AUTOSAR XML (schema 4-2-2)
package /STELLANTIS/EPT/ASWCs
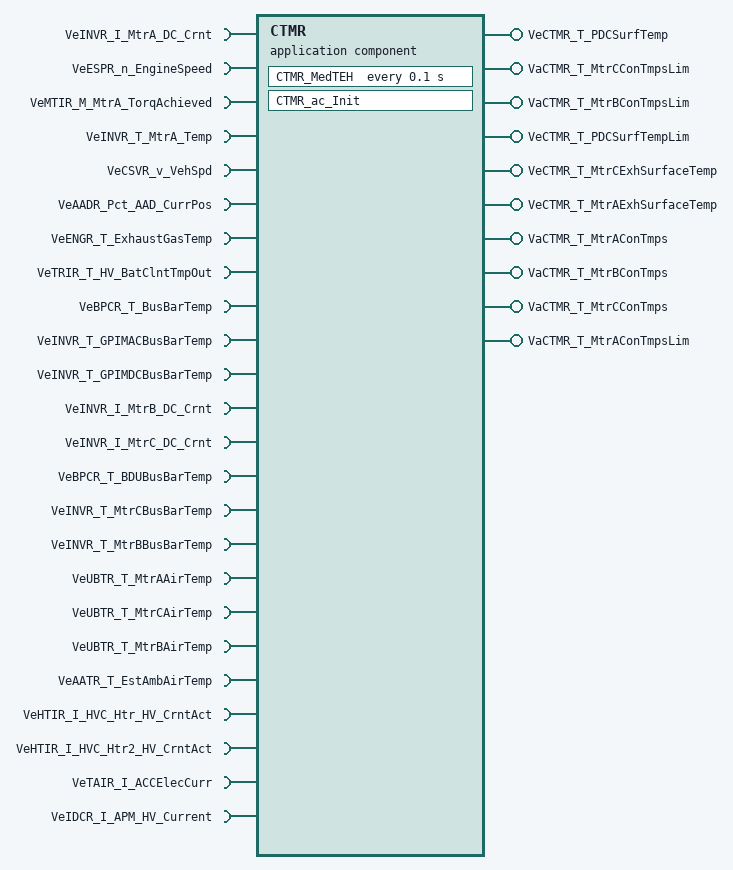
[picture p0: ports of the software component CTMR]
  application sw component type CTMR
    24 x require port, all with nonqueued-receiver-com-spec{data-element=Value, init-value=0}:
      VeINVR_I_MtrA_DC_Crnt: variation-point={short-label=vpVeINVR_I_MtrA_DC_Crnt, sw-syscond=1}, required-interface=VeINVR_I_MtrA_DC_Crnt
      VeESPR_n_EngineSpeed: variation-point={short-label=vpVeESPR_n_EngineSpeed, sw-syscond=1}, required-interface=VeESPR_n_EngineSpeed
      VeMTIR_M_MtrA_TorqAchieved: variation-point={short-label=vpVeMTIR_M_MtrA_TorqAchieved, sw-syscond=1}, required-interface=VeMTIR_M_MtrA_TorqAchieved
      VeINVR_T_MtrA_Temp: variation-point={short-label=vpVeINVR_T_MtrA_Temp, sw-syscond=1}, required-interface=VeINVR_T_MtrA_Temp
      VeCSVR_v_VehSpd: variation-point={short-label=vpVeCSVR_v_VehSpd, sw-syscond=1}, required-interface=VeCSVR_v_VehSpd
      VeAADR_Pct_AAD_CurrPos: variation-point={short-label=vpVeAADR_Pct_AAD_CurrPos, sw-syscond=1}, required-interface=VeAADR_Pct_AAD_CurrPos
      VeENGR_T_ExhaustGasTemp: variation-point={short-label=vpVeENGR_T_ExhaustGasTemp, sw-syscond=1}, required-interface=VeENGR_T_ExhaustGasTemp
      VeTRIR_T_HV_BatClntTmpOut: variation-point={short-label=vpVeTRIR_T_HV_BatClntTmpOut, sw-syscond=1}, required-interface=VeTRIR_T_HV_BatClntTmpOut
      VeBPCR_T_BusBarTemp: variation-point={short-label=vpVeBPCR_T_BusBarTemp, sw-syscond=1}, required-interface=VeBPCR_T_BusBarTemp
      VeINVR_T_GPIMACBusBarTemp: variation-point={short-label=vpVeINVR_T_GPIMACBusBarTemp, sw-syscond=1}, required-interface=VeINVR_T_GPIMACBusBarTemp
      VeINVR_T_GPIMDCBusBarTemp: variation-point={short-label=vpVeINVR_T_GPIMDCBusBarTemp, sw-syscond=1}, required-interface=VeINVR_T_GPIMDCBusBarTemp
      VeINVR_I_MtrB_DC_Crnt: variation-point={short-label=vpVeINVR_I_MtrB_DC_Crnt, sw-syscond=1}, required-interface=VeINVR_I_MtrB_DC_Crnt
      VeINVR_I_MtrC_DC_Crnt: variation-point={short-label=vpVeINVR_I_MtrC_DC_Crnt, sw-syscond=1}, required-interface=VeINVR_I_MtrC_DC_Crnt
      VeBPCR_T_BDUBusBarTemp: variation-point={short-label=vpVeBPCR_T_BDUBusBarTemp, sw-syscond=1}, required-interface=VeBPCR_T_BDUBusBarTemp
      VeINVR_T_MtrCBusBarTemp: variation-point={short-label=vpVeINVR_T_MtrCBusBarTemp, sw-syscond=1}, required-interface=VeINVR_T_MtrCBusBarTemp
      VeINVR_T_MtrBBusBarTemp: variation-point={short-label=vpVeINVR_T_MtrBBusBarTemp, sw-syscond=1}, required-interface=VeINVR_T_MtrBBusBarTemp
      VeUBTR_T_MtrAAirTemp: variation-point={short-label=vpVeUBTR_T_MtrAAirTemp, sw-syscond=1}, required-interface=VeUBTR_T_MtrAAirTemp
      VeUBTR_T_MtrCAirTemp: variation-point={short-label=vpVeUBTR_T_MtrCAirTemp, sw-syscond=1}, required-interface=VeUBTR_T_MtrCAirTemp
      VeUBTR_T_MtrBAirTemp: variation-point={short-label=vpVeUBTR_T_MtrBAirTemp, sw-syscond=1}, required-interface=VeUBTR_T_MtrBAirTemp
      VeAATR_T_EstAmbAirTemp: variation-point={short-label=vpVeAATR_T_EstAmbAirTemp, sw-syscond=1}, required-interface=VeAATR_T_EstAmbAirTemp
      VeHTIR_I_HVC_Htr_HV_CrntAct: variation-point={short-label=vpVeHTIR_I_HVC_Htr_HV_CrntAct, sw-syscond=1}, required-interface=VeHTIR_I_HVC_Htr_HV_CrntAct
      VeHTIR_I_HVC_Htr2_HV_CrntAct: variation-point={short-label=vpVeHTIR_I_HVC_Htr2_HV_CrntAct, sw-syscond=1}, required-interface=VeHTIR_I_HVC_Htr2_HV_CrntAct
      VeTAIR_I_ACCElecCurr: variation-point={short-label=vpVeTAIR_I_ACCElecCurr, sw-syscond=1}, required-interface=VeTAIR_I_ACCElecCurr
      VeIDCR_I_APM_HV_Current: variation-point={short-label=vpVeIDCR_I_APM_HV_Current, sw-syscond=1}, required-interface=VeIDCR_I_APM_HV_Current
    10 x provide port:
      VeCTMR_T_PDCSurfTemp: variation-point={short-label=vpVeCTMR_T_PDCSurfTemp, sw-syscond=1}, nonqueued-sender-com-spec{data-element=Value, init-value=0}, provided-interface=VeCTMR_T_PDCSurfTemp
      VaCTMR_T_MtrCConTmpsLim: variation-point={short-label=vpVaCTMR_T_MtrCConTmpsLim, sw-syscond=1}, nonqueued-sender-com-spec{data-element=Value, init-value=[0, 0]}, provided-interface=VaCTMR_T_MtrCConTmpsLim
      VaCTMR_T_MtrBConTmpsLim: variation-point={short-label=vpVaCTMR_T_MtrBConTmpsLim, sw-syscond=1}, nonqueued-sender-com-spec{data-element=Value, init-value=[0, 0]}, provided-interface=VaCTMR_T_MtrBConTmpsLim
      VeCTMR_T_PDCSurfTempLim: variation-point={short-label=vpVeCTMR_T_PDCSurfTempLim, sw-syscond=1}, nonqueued-sender-com-spec{data-element=Value, init-value=0}, provided-interface=VeCTMR_T_PDCSurfTempLim
      VeCTMR_T_MtrCExhSurfaceTemp: variation-point={short-label=vpVeCTMR_T_MtrCExhSurfaceTemp, sw-syscond=1}, nonqueued-sender-com-spec{data-element=Value, init-value=0}, provided-interface=VeCTMR_T_MtrCExhSurfaceTemp
      VeCTMR_T_MtrAExhSurfaceTemp: variation-point={short-label=vpVeCTMR_T_MtrAExhSurfaceTemp, sw-syscond=1}, nonqueued-sender-com-spec{data-element=Value, init-value=0}, provided-interface=VeCTMR_T_MtrAExhSurfaceTemp
      VaCTMR_T_MtrAConTmps: variation-point={short-label=vpVaCTMR_T_MtrAConTmps, sw-syscond=1}, nonqueued-sender-com-spec{data-element=Value, init-value=[0, 0, 0, 0]}, provided-interface=VaCTMR_T_MtrAConTmps
      VaCTMR_T_MtrBConTmps: variation-point={short-label=vpVaCTMR_T_MtrBConTmps, sw-syscond=1}, nonqueued-sender-com-spec{data-element=Value, init-value=[0, 0]}, provided-interface=VaCTMR_T_MtrBConTmps
      VaCTMR_T_MtrCConTmps: variation-point={short-label=vpVaCTMR_T_MtrCConTmps, sw-syscond=1}, nonqueued-sender-com-spec{data-element=Value, init-value=[0, 0]}, provided-interface=VaCTMR_T_MtrCConTmps
      VaCTMR_T_MtrAConTmpsLim: variation-point={short-label=vpVaCTMR_T_MtrAConTmpsLim, sw-syscond=1}, nonqueued-sender-com-spec{data-element=Value, init-value=[0, 0, 0, 0]}, provided-interface=VaCTMR_T_MtrAConTmpsLim
    behavior IB_CTMR: data-type-mapping=msADTtoIDTMapping, handle-termination-and-restart=NO-SUPPORT
      timing event Event_MedTEH: start-on-event=CTMR_MedTEH, period=0.1
      init event Event_CTMR_ac_Init: start-on-event=CTMR_ac_Init
      runnable CTMR_ac_Init
        data-send-points:
          6 x access:
            OUT_VaCTMR_T_MtrCConTmpsLim_Value: accessed-variable=VaCTMR_T_MtrCConTmpsLim.Value, variation-point={short-label=vpOUT_VaCTMR_T_MtrCConTmpsLim_Value, sw-syscond=1}
            OUT_VaCTMR_T_MtrBConTmpsLim_Value: accessed-variable=VaCTMR_T_MtrBConTmpsLim.Value, variation-point={short-label=vpOUT_VaCTMR_T_MtrBConTmpsLim_Value, sw-syscond=1}
            OUT_VaCTMR_T_MtrAConTmps_Value: accessed-variable=VaCTMR_T_MtrAConTmps.Value, variation-point={short-label=vpOUT_VaCTMR_T_MtrAConTmps_Value, sw-syscond=1}
            OUT_VaCTMR_T_MtrBConTmps_Value: accessed-variable=VaCTMR_T_MtrBConTmps.Value, variation-point={short-label=vpOUT_VaCTMR_T_MtrBConTmps_Value, sw-syscond=1}
            OUT_VaCTMR_T_MtrCConTmps_Value: accessed-variable=VaCTMR_T_MtrCConTmps.Value, variation-point={short-label=vpOUT_VaCTMR_T_MtrCConTmps_Value, sw-syscond=1}
            OUT_VaCTMR_T_MtrAConTmpsLim_Value: accessed-variable=VaCTMR_T_MtrAConTmpsLim.Value, variation-point={short-label=vpOUT_VaCTMR_T_MtrAConTmpsLim_Value, sw-syscond=1}
      runnable CTMR_MedTEH: variation-point={short-label=vpCTMR_MedTEH, sw-syscond=1}
        data-receive-point-by-arguments:
          24 x access:
            IN_VeAADR_Pct_AAD_CurrPos_Value: accessed-variable=VeAADR_Pct_AAD_CurrPos.Value, variation-point={short-label=vpIN_VeAADR_Pct_AAD_CurrPos_Value, sw-syscond=1}
            IN_VeAATR_T_EstAmbAirTemp_Value: accessed-variable=VeAATR_T_EstAmbAirTemp.Value, variation-point={short-label=vpIN_VeAATR_T_EstAmbAirTemp_Value, sw-syscond=1}
            IN_VeBPCR_T_BDUBusBarTemp_Value: accessed-variable=VeBPCR_T_BDUBusBarTemp.Value, variation-point={short-label=vpIN_VeBPCR_T_BDUBusBarTemp_Value, sw-syscond=1}
            IN_VeBPCR_T_BusBarTemp_Value: accessed-variable=VeBPCR_T_BusBarTemp.Value, variation-point={short-label=vpIN_VeBPCR_T_BusBarTemp_Value, sw-syscond=1}
            IN_VeCSVR_v_VehSpd_Value: accessed-variable=VeCSVR_v_VehSpd.Value, variation-point={short-label=vpIN_VeCSVR_v_VehSpd_Value, sw-syscond=1}
            IN_VeENGR_T_ExhaustGasTemp_Value: accessed-variable=VeENGR_T_ExhaustGasTemp.Value, variation-point={short-label=vpIN_VeENGR_T_ExhaustGasTemp_Value, sw-syscond=1}
            IN_VeESPR_n_EngineSpeed_Value: accessed-variable=VeESPR_n_EngineSpeed.Value, variation-point={short-label=vpIN_VeESPR_n_EngineSpeed_Value, sw-syscond=1}
            IN_VeHTIR_I_HVC_Htr2_HV_CrntAct_Value: accessed-variable=VeHTIR_I_HVC_Htr2_HV_CrntAct.Value, variation-point={short-label=vpIN_VeHTIR_I_HVC_Htr2_HV_CrntAct_Value, sw-syscond=1}
            IN_VeHTIR_I_HVC_Htr_HV_CrntAct_Value: accessed-variable=VeHTIR_I_HVC_Htr_HV_CrntAct.Value, variation-point={short-label=vpIN_VeHTIR_I_HVC_Htr_HV_CrntAct_Value, sw-syscond=1}
            IN_VeIDCR_I_APM_HV_Current_Value: accessed-variable=VeIDCR_I_APM_HV_Current.Value, variation-point={short-label=vpIN_VeIDCR_I_APM_HV_Current_Value, sw-syscond=1}
            IN_VeINVR_I_MtrA_DC_Crnt_Value: accessed-variable=VeINVR_I_MtrA_DC_Crnt.Value, variation-point={short-label=vpIN_VeINVR_I_MtrA_DC_Crnt_Value, sw-syscond=1}
            IN_VeINVR_I_MtrB_DC_Crnt_Value: accessed-variable=VeINVR_I_MtrB_DC_Crnt.Value, variation-point={short-label=vpIN_VeINVR_I_MtrB_DC_Crnt_Value, sw-syscond=1}
            IN_VeINVR_I_MtrC_DC_Crnt_Value: accessed-variable=VeINVR_I_MtrC_DC_Crnt.Value, variation-point={short-label=vpIN_VeINVR_I_MtrC_DC_Crnt_Value, sw-syscond=1}
            IN_VeINVR_T_GPIMACBusBarTemp_Value: accessed-variable=VeINVR_T_GPIMACBusBarTemp.Value, variation-point={short-label=vpIN_VeINVR_T_GPIMACBusBarTemp_Value, sw-syscond=1}
            IN_VeINVR_T_GPIMDCBusBarTemp_Value: accessed-variable=VeINVR_T_GPIMDCBusBarTemp.Value, variation-point={short-label=vpIN_VeINVR_T_GPIMDCBusBarTemp_Value, sw-syscond=1}
            IN_VeINVR_T_MtrA_Temp_Value: accessed-variable=VeINVR_T_MtrA_Temp.Value, variation-point={short-label=vpIN_VeINVR_T_MtrA_Temp_Value, sw-syscond=1}
            IN_VeINVR_T_MtrBBusBarTemp_Value: accessed-variable=VeINVR_T_MtrBBusBarTemp.Value, variation-point={short-label=vpIN_VeINVR_T_MtrBBusBarTemp_Value, sw-syscond=1}
            IN_VeINVR_T_MtrCBusBarTemp_Value: accessed-variable=VeINVR_T_MtrCBusBarTemp.Value, variation-point={short-label=vpIN_VeINVR_T_MtrCBusBarTemp_Value, sw-syscond=1}
            IN_VeMTIR_M_MtrA_TorqAchieved_Value: accessed-variable=VeMTIR_M_MtrA_TorqAchieved.Value, variation-point={short-label=vpIN_VeMTIR_M_MtrA_TorqAchieved_Value, sw-syscond=1}
            IN_VeTAIR_I_ACCElecCurr_Value: accessed-variable=VeTAIR_I_ACCElecCurr.Value, variation-point={short-label=vpIN_VeTAIR_I_ACCElecCurr_Value, sw-syscond=1}
            IN_VeTRIR_T_HV_BatClntTmpOut_Value: accessed-variable=VeTRIR_T_HV_BatClntTmpOut.Value, variation-point={short-label=vpIN_VeTRIR_T_HV_BatClntTmpOut_Value, sw-syscond=1}
            IN_VeUBTR_T_MtrAAirTemp_Value: accessed-variable=VeUBTR_T_MtrAAirTemp.Value, variation-point={short-label=vpIN_VeUBTR_T_MtrAAirTemp_Value, sw-syscond=1}
            IN_VeUBTR_T_MtrBAirTemp_Value: accessed-variable=VeUBTR_T_MtrBAirTemp.Value, variation-point={short-label=vpIN_VeUBTR_T_MtrBAirTemp_Value, sw-syscond=1}
            IN_VeUBTR_T_MtrCAirTemp_Value: accessed-variable=VeUBTR_T_MtrCAirTemp.Value, variation-point={short-label=vpIN_VeUBTR_T_MtrCAirTemp_Value, sw-syscond=1}
        data-send-points:
          10 x access:
            OUT_VeCTMR_T_PDCSurfTempLim_Value: accessed-variable=VeCTMR_T_PDCSurfTempLim.Value, variation-point={short-label=vpOUT_VeCTMR_T_PDCSurfTempLim_Value, sw-syscond=1}
            OUT_VaCTMR_T_MtrAConTmps_Value: accessed-variable=VaCTMR_T_MtrAConTmps.Value, variation-point={short-label=vpOUT_VaCTMR_T_MtrAConTmps_Value, sw-syscond=1}
            OUT_VeCTMR_T_PDCSurfTemp_Value: accessed-variable=VeCTMR_T_PDCSurfTemp.Value, variation-point={short-label=vpOUT_VeCTMR_T_PDCSurfTemp_Value, sw-syscond=1}
            OUT_VaCTMR_T_MtrAConTmpsLim_Value: accessed-variable=VaCTMR_T_MtrAConTmpsLim.Value, variation-point={short-label=vpOUT_VaCTMR_T_MtrAConTmpsLim_Value, sw-syscond=1}
            OUT_VaCTMR_T_MtrBConTmpsLim_Value: accessed-variable=VaCTMR_T_MtrBConTmpsLim.Value, variation-point={short-label=vpOUT_VaCTMR_T_MtrBConTmpsLim_Value, sw-syscond=1}
            OUT_VaCTMR_T_MtrBConTmps_Value: accessed-variable=VaCTMR_T_MtrBConTmps.Value, variation-point={short-label=vpOUT_VaCTMR_T_MtrBConTmps_Value, sw-syscond=1}
            OUT_VaCTMR_T_MtrCConTmpsLim_Value: accessed-variable=VaCTMR_T_MtrCConTmpsLim.Value, variation-point={short-label=vpOUT_VaCTMR_T_MtrCConTmpsLim_Value, sw-syscond=1}
            OUT_VaCTMR_T_MtrCConTmps_Value: accessed-variable=VaCTMR_T_MtrCConTmps.Value, variation-point={short-label=vpOUT_VaCTMR_T_MtrCConTmps_Value, sw-syscond=1}
            OUT_VeCTMR_T_MtrAExhSurfaceTemp_Value: accessed-variable=VeCTMR_T_MtrAExhSurfaceTemp.Value, variation-point={short-label=vpOUT_VeCTMR_T_MtrAExhSurfaceTemp_Value, sw-syscond=1}
            OUT_VeCTMR_T_MtrCExhSurfaceTemp_Value: accessed-variable=VeCTMR_T_MtrCExhSurfaceTemp.Value, variation-point={short-label=vpOUT_VeCTMR_T_MtrCExhSurfaceTemp_Value, sw-syscond=1}
      5 x variation point proxy, all with category=CONDITION:
        Variant_CTMR_1: condition-access=1
        Variant_CTMR_2: condition-access=0
        Variant_CTMR_3: condition-access=1
        Variant_CTMR_4: condition-access=1
        Variant_CTMR_5: condition-access=0
